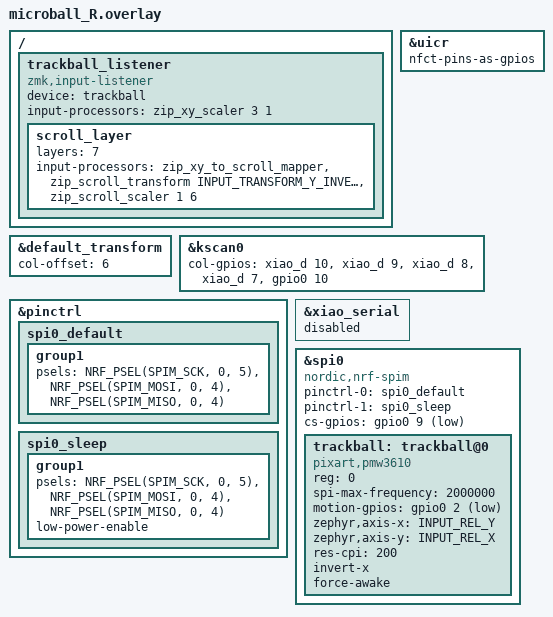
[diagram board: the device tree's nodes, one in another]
#include "microball.dtsi"
#include <input/processors.dtsi>
#include <dt-bindings/input/input-event-codes.h>
#include <dt-bindings/zmk/input_transform.h>

&uicr {
    nfct-pins-as-gpios;
};

&default_transform {
    col-offset = <6>;
};

&kscan0 {
        col-gpios
            = <&xiao_d 10 GPIO_ACTIVE_HIGH>
            , <&xiao_d 9 GPIO_ACTIVE_HIGH> 
            , <&xiao_d 8 GPIO_ACTIVE_HIGH> 
            , <&xiao_d 7 GPIO_ACTIVE_HIGH> 
            , <&gpio0 10 GPIO_ACTIVE_HIGH>
            ;
};

/ {
    trackball_listener {
        compatible = "zmk,input-listener";
        device = <&trackball>;

        /* Base: scale up cursor movement (low CPI + large scaler = fewer events, same speed) */
        input-processors = <&zip_xy_scaler 3 1>;

        /* Layer 7 (SCROLL): convert trackball to scroll instead of cursor */
        scroll_layer {
            layers = <7>;
            input-processors =
                <&zip_xy_to_scroll_mapper>,
                <&zip_scroll_transform INPUT_TRANSFORM_Y_INVERT>,
                <&zip_scroll_scaler 1 6>;
        };
    };
};

&pinctrl {
    spi0_default: spi0_default {
        group1 {
            psels = <NRF_PSEL(SPIM_SCK, 0, 5)>,
                <NRF_PSEL(SPIM_MOSI, 0, 4)>,
                <NRF_PSEL(SPIM_MISO, 0, 4)>;
        };
    };

    spi0_sleep: spi0_sleep {
        group1 {
            psels = <NRF_PSEL(SPIM_SCK, 0, 5)>,
                <NRF_PSEL(SPIM_MOSI, 0, 4)>,
                <NRF_PSEL(SPIM_MISO, 0, 4)>;
            low-power-enable;
        };
    };
};

&xiao_serial { status = "disabled"; };

&spi0 {
    status = "okay";
    compatible = "nordic,nrf-spim";
    pinctrl-0 = <&spi0_default>;
    pinctrl-1 = <&spi0_sleep>;
    pinctrl-names = "default", "sleep";
    cs-gpios = <&gpio0 9 GPIO_ACTIVE_LOW>;

    trackball: trackball@0 {
        status = "okay";
        compatible = "pixart,pmw3610";
        reg = <0>;
        spi-max-frequency = <2000000>;
        motion-gpios = <&gpio0 2 (GPIO_ACTIVE_LOW | GPIO_PULL_UP)>;
        zephyr,axis-x = <INPUT_REL_Y>;
        zephyr,axis-y = <INPUT_REL_X>;
        res-cpi = <200>;
        invert-x;
        force-awake;
    };
};


